# STM32G544xx register map
File version: 1.0
Registers are 32-bit, read-write, reset 0x0 unless marked. A register's access mark holds for its fields unless they carry their own. Offsets are from the block's base; [hi:lo] are bit positions; {n}, {i} and the like mark numbered series.

## EXTI — Extended interrupts and event controller (EXTI)
Base 0x44022000
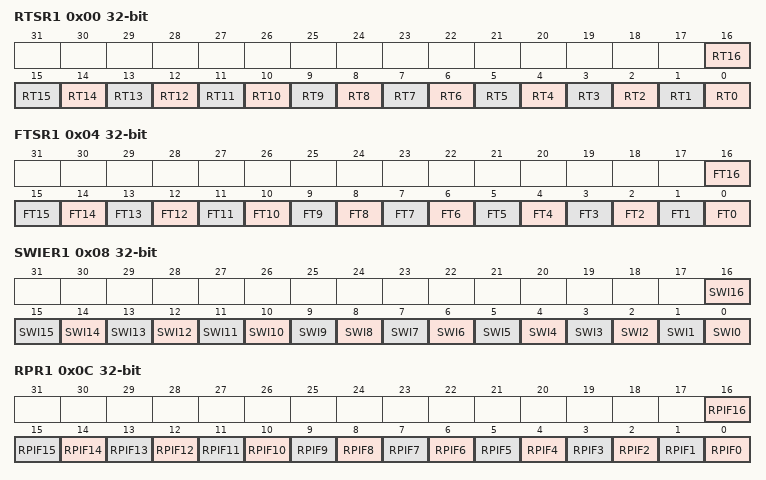
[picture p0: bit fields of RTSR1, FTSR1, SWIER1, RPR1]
0x00 RTSR1 — EXTI rising trigger selection register 1
  [n] RT{n} (n=0..16)
0x04 FTSR1 — EXTI falling trigger selection register 1
  [n] FT{n} (n=0..16)
0x08 SWIER1 — EXTI software interrupt event register 1
  [n] SWI{n} (n=0..16) — Software interrupt on event x
0x0C RPR1 — EXTI rising edge pending register 1
  [n] RPIF{n} (n=0..16)
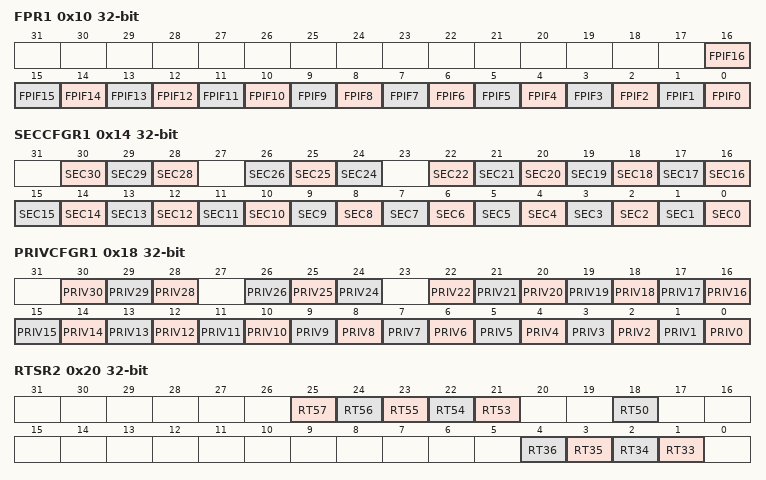
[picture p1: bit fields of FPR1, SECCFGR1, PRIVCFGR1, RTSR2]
0x10 FPR1 — EXTI falling edge pending register 1
  [n] FPIF{n} (n=0..16)
0x14 SECCFGR1 — EXTI security configuration register 1
  [30] SEC30 — Security enable on event input x
  [29] SEC29 — Security enable on event input x
  [28] SEC28 — Security enable on event input x
  [26] SEC26 — Security enable on event input x
  [25] SEC25 — Security enable on event input x
  [24] SEC24 — Security enable on event input x
  [n] SEC{n} (n=0..22) — Security enable on event input x
0x18 PRIVCFGR1 — EXTI privilege configuration register 1
  [30] PRIV30 — Security enable on event input x
  [29] PRIV29 — Security enable on event input x
  [28] PRIV28 — Security enable on event input x
  [26] PRIV26 — Security enable on event input x
  [25] PRIV25 — Security enable on event input x
  [24] PRIV24 — Security enable on event input x
  [n] PRIV{n} (n=0..22) — Security enable on event input x
0x20 RTSR2 — EXTI rising trigger selection register 2
  [n-32] RT{n} (n=53..57), [18] RT50, [n-32] RT{n} (n=33..36)
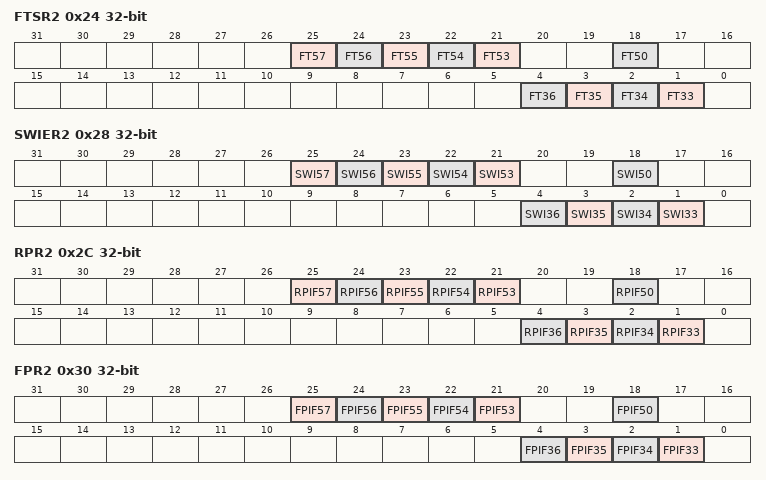
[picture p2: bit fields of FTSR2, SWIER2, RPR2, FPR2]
0x24 FTSR2 — EXTI falling trigger selection register 2
  [n-32] FT{n} (n=53..57), [18] FT50, [n-32] FT{n} (n=33..36)
0x28 SWIER2 — EXTI software interrupt event register 2
  [n-32] SWI{n} (n=53..57) — Software interrupt on event x
  [18] SWI50 — Software interrupt on event x
  [n-32] SWI{n} (n=33..36) — Software interrupt on event x
0x2C RPR2 — EXTI rising edge pending register 2
  [n-32] RPIF{n} (n=53..57), [18] RPIF50, [n-32] RPIF{n} (n=33..36)
0x30 FPR2 — EXTI falling edge pending register 2
  [n-32] FPIF{n} (n=53..57), [18] FPIF50, [n-32] FPIF{n} (n=33..36)
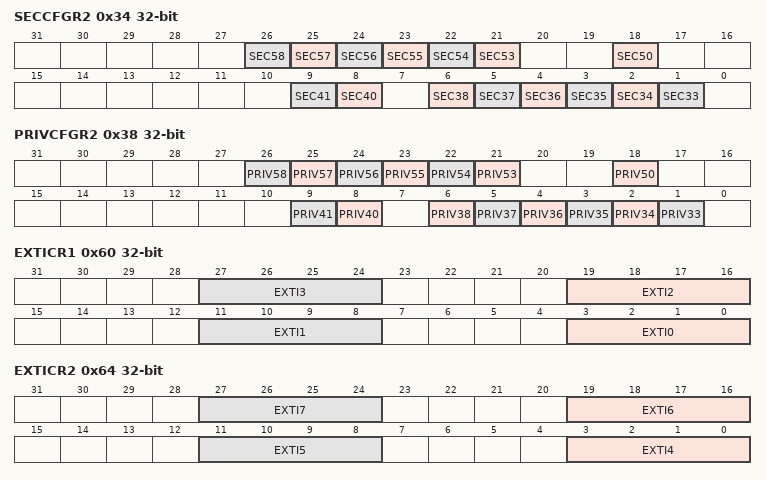
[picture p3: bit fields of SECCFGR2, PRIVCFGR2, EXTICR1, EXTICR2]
0x34 SECCFGR2 — EXTI security configuration register 2
  [n-32] SEC{n} (n=53..58) — Security enable on event input x
  [18] SEC50 — Security enable on event input x
  [9] SEC41 — Security enable on event input x
  [8] SEC40 — Security enable on event input x
  [n-32] SEC{n} (n=33..38) — Security enable on event input x
0x38 PRIVCFGR2 — EXTI privilege configuration register 2
  [n-32] PRIV{n} (n=53..58) — Security enable on event input x
  [18] PRIV50 — Security enable on event input x
  [9] PRIV41 — Security enable on event input x
  [8] PRIV40 — Security enable on event input x
  [n-32] PRIV{n} (n=33..38) — Security enable on event input x
0x60 EXTICR1 — EXTI external interrupt selection register
  [8n+3:8n] EXTI{n} (n=0..3) — EXTI {n} configuration
0x64 EXTICR2 — EXTI external interrupt selection register
  [8n-29:8n-32] EXTI{n} (n=4..7) — EXTI {n} configuration
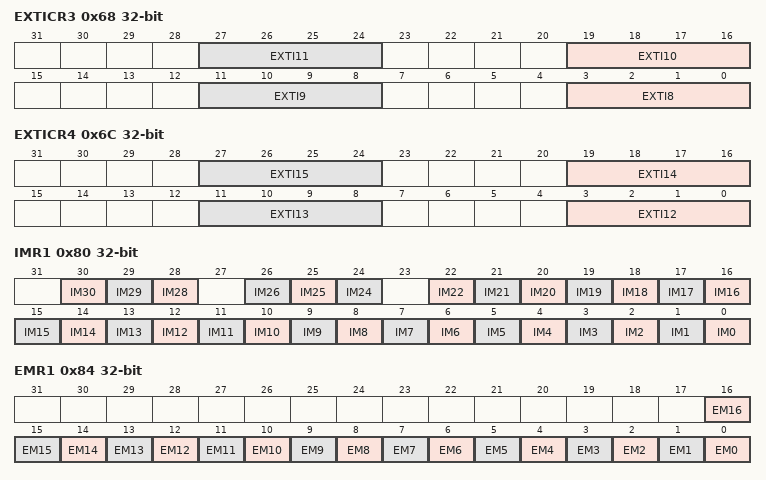
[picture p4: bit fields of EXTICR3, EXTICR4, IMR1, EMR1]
0x68 EXTICR3 — EXTI external interrupt selection register
  [8n-61:8n-64] EXTI{n} (n=8..11) — EXTI {n} configuration
0x6C EXTICR4 — EXTI external interrupt selection register
  [8n-93:8n-96] EXTI{n} (n=12..15) — EXTI {n} configuration
0x70 LOCKR — EXTI lock register
  [0] LOCK
0x80 IMR1 — EXTI CPU wake-up with interrupt mask register 1
  [30] IM30, [29] IM29, [28] IM28, [26] IM26, [25] IM25, [24] IM24, [n] IM{n} (n=0..22)
0x84 EMR1 — EXTI CPU wake-up with event mask register 1
  [n] EM{n} (n=0..16)
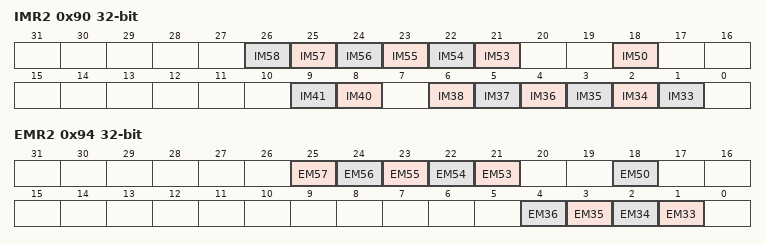
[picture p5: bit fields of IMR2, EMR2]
0x90 IMR2 — EXTI CPU wake-up with interrupt mask register 2
  [n-32] IM{n} (n=53..58), [18] IM50, [9] IM41, [8] IM40, [n-32] IM{n} (n=33..38)
0x94 EMR2 — EXTI CPU wake-up with event mask register 2
  [n-32] EM{n} (n=53..57), [18] EM50, [n-32] EM{n} (n=33..36)

## DBGMCU — Microcontroller debug unit (DBGMCU)
Base 0x44026000
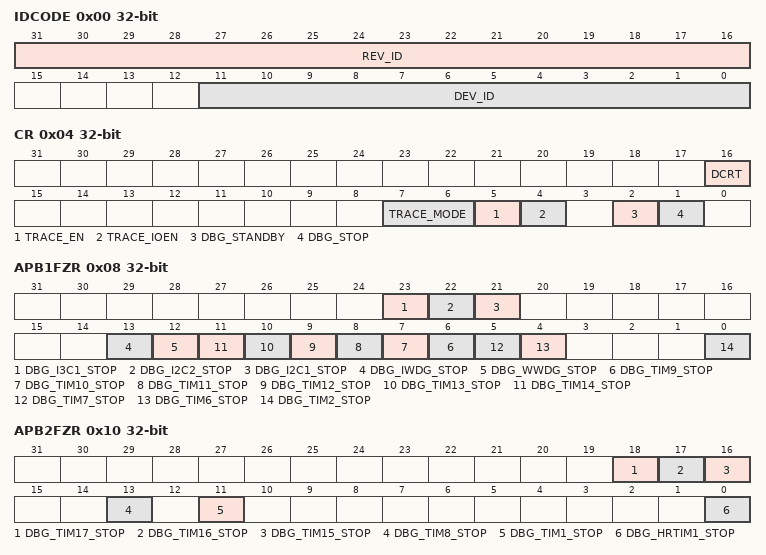
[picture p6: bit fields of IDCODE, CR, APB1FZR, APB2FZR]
0x00 IDCODE ro — DBGMCU identity code register
  [31:16] REV_ID — Revision
  [11:0] DEV_ID
0x04 CR — DBGMCU configuration register
  [16] DCRT
  [7:6] TRACE_MODE
  [5] TRACE_EN
  [4] TRACE_IOEN — trace pin enable
  [2] DBG_STANDBY
  [1] DBG_STOP
0x08 APB1FZR — DBGMCU APB1 peripheral freeze register
  [23] DBG_I3C1_STOP, [22] DBG_I2C2_STOP, [21] DBG_I2C1_STOP, [13] DBG_IWDG_STOP, [12] DBG_WWDG_STOP, [n-3] DBG_TIM{n}_STOP (n=9..14), [5] DBG_TIM7_STOP, [4] DBG_TIM6_STOP, [0] DBG_TIM2_STOP
0x10 APB2FZR — DBGMCU APB2 peripheral freeze register
  [18] DBG_TIM17_STOP, [17] DBG_TIM16_STOP, [16] DBG_TIM15_STOP, [13] DBG_TIM8_STOP, [11] DBG_TIM1_STOP, [0] DBG_HRTIM1_STOP
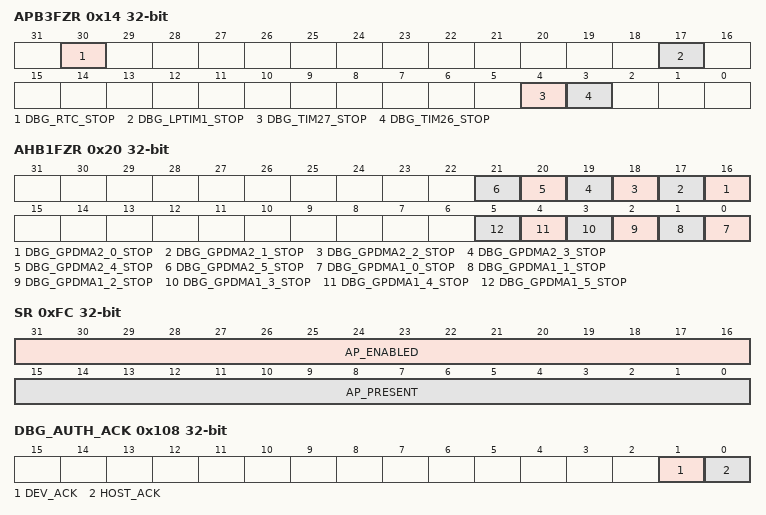
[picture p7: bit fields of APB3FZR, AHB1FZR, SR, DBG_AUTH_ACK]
0x14 APB3FZR — DBGMCU APB3 peripheral freeze register
  [30] DBG_RTC_STOP — RTC stop in debug
  [17] DBG_LPTIM1_STOP
  [4] DBG_TIM27_STOP
  [3] DBG_TIM26_STOP
0x20 AHB1FZR — DBGMCU AHB1 peripheral freeze register
  [n+16] DBG_GPDMA2_{n}_STOP (n=0..5), [n] DBG_GPDMA1_{n}_STOP (n=0..5)
0x80 EDBGRQ — DBGMCU EDBGRQ debug request control
  [0] DBG_CPU
0xFC SR ro — DBGMCU status register
  [31:16] AP_ENABLED, [15:0] AP_PRESENT
0x100 DBG_AUTH_HOST — DBGMCU debug authentication mailbox host register
  [31:0] MESSAGE
0x104 DBG_AUTH_DEVICE — DBGMCU debug authentication mailbox device register
  [31:0] MESSAGE
0x108 DBG_AUTH_ACK ro — DBGMCU debug authentication mailbox acknowledge register
  [1] DEV_ACK, [0] HOST_ACK
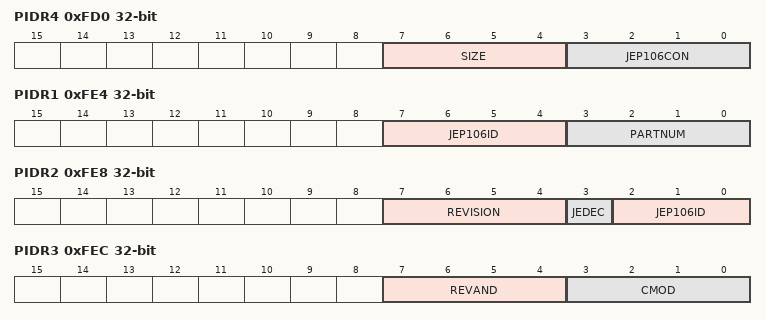
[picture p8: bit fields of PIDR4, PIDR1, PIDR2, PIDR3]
0xFD0 PIDR4 ro — DBGMCU CoreSight peripheral identity register 4
  [7:4] SIZE, [3:0] JEP106CON
0xFE0 PIDR0 ro — DBGMCU CoreSight peripheral identity register 0
  [7:0] PARTNUM
0xFE4 PIDR1 ro — DBGMCU CoreSight peripheral identity register 1
  [7:4] JEP106ID, [3:0] PARTNUM
0xFE8 PIDR2 ro — DBGMCU CoreSight peripheral identity register 2
  [7:4] REVISION, [3] JEDEC, [2:0] JEP106ID
0xFEC PIDR3 ro — DBGMCU CoreSight peripheral identity register 3
  [7:4] REVAND — metal fix version
  [3:0] CMOD — customer modified
0xFF0 CIDR0 ro — DBGMCU CoreSight component identity register 0
  [7:0] PREAMBLE
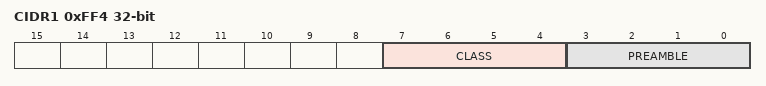
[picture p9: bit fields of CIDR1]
0xFF4 CIDR1 ro — DBGMCU CoreSight component identity register 1
  [7:4] CLASS, [3:0] PREAMBLE
0xFF8 CIDR2 ro — DBGMCU CoreSight component identity register 2
  [7:0] PREAMBLE
0xFFC CIDR3 ro — DBGMCU CoreSight component identity register 3
  [7:0] PREAMBLE
